# N32G003 register map
Vendor: Nationstech Ltd.; File version: 1.0
Registers are 32-bit, read-write, reset 0x0 unless marked. A register's access mark holds for its fields unless they carry their own. Offsets are from the block's base; [hi:lo] are bit positions; {n}, {i} and the like mark numbered series.

## SPI — Serial peripheral interface
Base 0x40005800
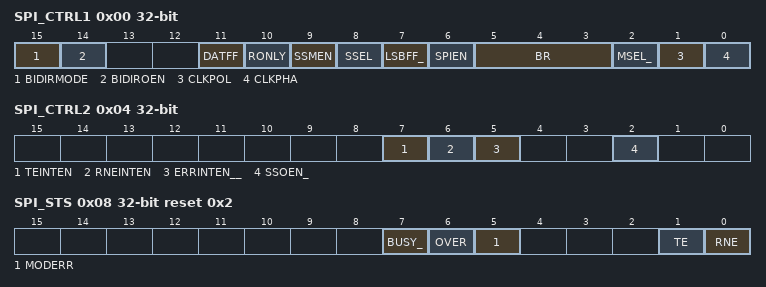
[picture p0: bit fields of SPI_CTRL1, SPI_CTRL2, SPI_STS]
0x00 SPI_CTRL1
  [15] BIDIRMODE, [14] BIDIROEN, [11] DATFF, [10] RONLY, [9] SSMEN, [8] SSEL, [7] LSBFF_, [6] SPIEN, [5:3] BR, [2] MSEL_, [1] CLKPOL, [0] CLKPHA
0x04 SPI_CTRL2
  [7] TEINTEN, [6] RNEINTEN, [5] ERRINTEN__, [2] SSOEN_
0x08 SPI_STS reset 0x2
  [7] BUSY_, [6] OVER, [5] MODERR, [1] TE, [0] RNE
0x0C SPI_DAT
  [15:0] DAT

## TIM1 — Advanced timer
Base 0x40000C00
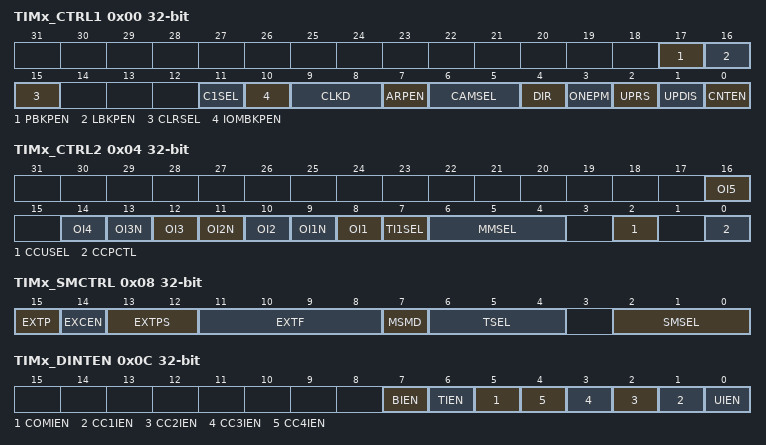
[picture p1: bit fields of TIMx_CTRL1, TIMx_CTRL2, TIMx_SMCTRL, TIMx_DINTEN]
0x00 TIMx_CTRL1
  [17] PBKPEN, [16] LBKPEN, [15] CLRSEL, [11] C1SEL, [10] IOMBKPEN, [9:8] CLKD, [7] ARPEN, [6:5] CAMSEL, [4] DIR, [3] ONEPM, [2] UPRS, [1] UPDIS, [0] CNTEN
0x04 TIMx_CTRL2
  [2n+6] OI{n} (n=1..5), [13] OI3N, [11] OI2N, [9] OI1N, [7] TI1SEL, [6:4] MMSEL, [2] CCUSEL, [0] CCPCTL
0x08 TIMx_SMCTRL
  [15] EXTP, [14] EXCEN, [13:12] EXTPS, [11:8] EXTF, [7] MSMD, [6:4] TSEL, [2:0] SMSEL
0x0C TIMx_DINTEN
  [7] BIEN, [6] TIEN, [5] COMIEN, [n] CC{n}IEN (n=1..4), [0] UIEN
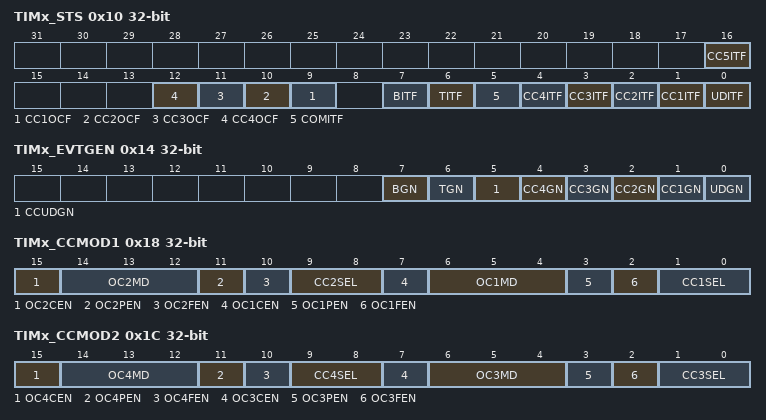
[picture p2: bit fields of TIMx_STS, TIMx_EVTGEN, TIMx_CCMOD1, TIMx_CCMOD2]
0x10 TIMx_STS
  [16] CC5ITF, [n+8] CC{n}OCF (n=1..4), [7] BITF, [6] TITF, [5] COMITF, [n] CC{n}ITF (n=1..4), [0] UDITF
0x14 TIMx_EVTGEN
  [7] BGN, [6] TGN, [5] CCUDGN, [n] CC{n}GN (n=1..4), [0] UDGN
0x18 TIMx_CCMOD1
  [15] OC2CEN, [14:12] OC2MD, [11] OC2PEN, [10] OC2FEN, [9:8] CC2SEL, [7] OC1CEN, [6:4] OC1MD, [3] OC1PEN, [2] OC1FEN, [1:0] CC1SEL
0x1C TIMx_CCMOD2
  [15] OC4CEN
  [14:12] OC4MD — OC4M
  [11] OC4PEN
  [10] OC4FEN
  [9:8] CC4SEL
  [7] OC3CEN
  [6:4] OC3MD — OC3M
  [3] OC3PEN
  [2] OC3FEN
  [1:0] CC3SEL
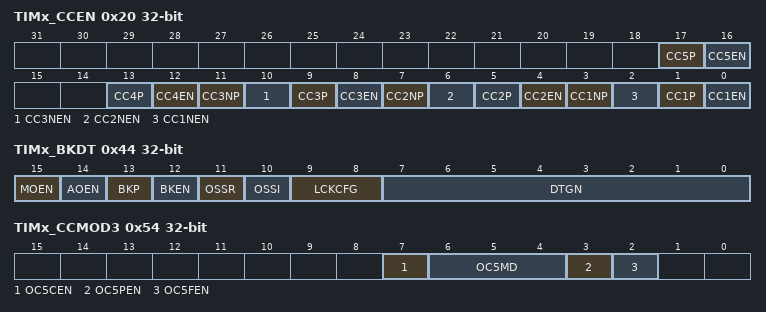
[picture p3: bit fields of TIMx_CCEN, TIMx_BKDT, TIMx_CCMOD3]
0x20 TIMx_CCEN
  [4n-3] CC{n}P (n=1..5), [4n-4] CC{n}EN (n=1..5), [11] CC3NP, [10] CC3NEN, [7] CC2NP, [6] CC2NEN, [3] CC1NP, [2] CC1NEN
0x24 TIMx_CNT
  [15:0] CNT
0x28 TIMx_PSC
  [15:0] PSC
0x2C TIMx_AR
  [15:0] AR
0x30 TIMx_REPCNT
  [7:0] REPCNT
{0x30+4i} TIMx_CCDAT{i} (i=1..4)
  [15:0] CCDAT{i}
0x44 TIMx_BKDT
  [15] MOEN, [14] AOEN, [13] BKP, [12] BKEN, [11] OSSR, [10] OSSI, [9:8] LCKCFG, [7:0] DTGN
0x54 TIMx_CCMOD3
  [7] OC5CEN, [6:4] OC5MD, [3] OC5PEN, [2] OC5FEN
0x58 TIMx_CCDAT5
  [15:0] CCDAT5

## TIM3 — General purpose timer
Base 0x40000400
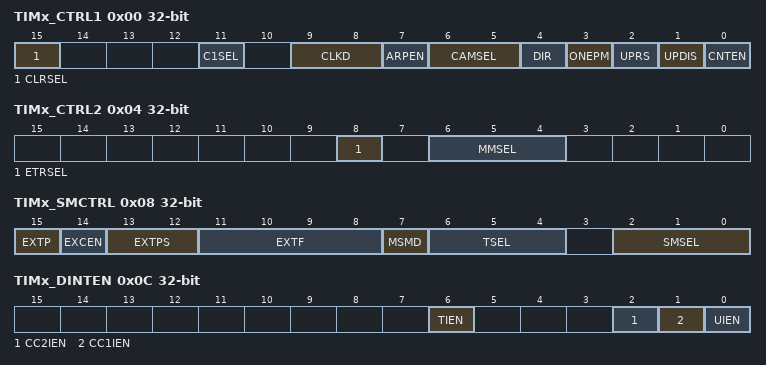
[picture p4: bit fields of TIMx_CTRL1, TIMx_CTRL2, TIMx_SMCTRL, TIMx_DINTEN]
0x00 TIMx_CTRL1
  [15] CLRSEL, [11] C1SEL, [9:8] CLKD, [7] ARPEN, [6:5] CAMSEL, [4] DIR, [3] ONEPM, [2] UPRS, [1] UPDIS, [0] CNTEN
0x04 TIMx_CTRL2
  [8] ETRSEL, [6:4] MMSEL
0x08 TIMx_SMCTRL
  [15] EXTP, [14] EXCEN, [13:12] EXTPS, [11:8] EXTF, [7] MSMD, [6:4] TSEL, [2:0] SMSEL
0x0C TIMx_DINTEN
  [6] TIEN, [2] CC2IEN, [1] CC1IEN, [0] UIEN
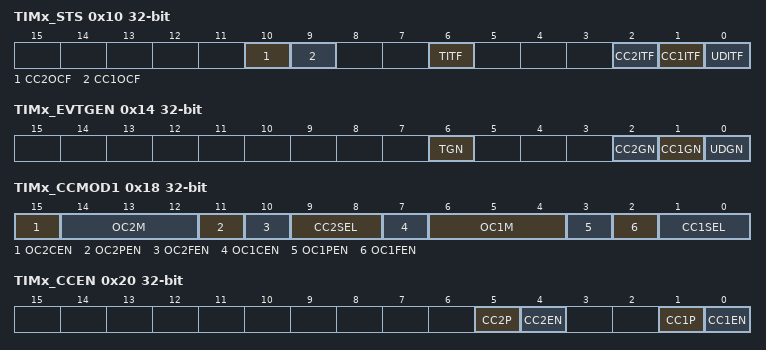
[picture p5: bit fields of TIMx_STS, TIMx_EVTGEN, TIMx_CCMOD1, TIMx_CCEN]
0x10 TIMx_STS
  [10] CC2OCF, [9] CC1OCF, [6] TITF, [2] CC2ITF, [1] CC1ITF, [0] UDITF
0x14 TIMx_EVTGEN
  [6] TGN, [2] CC2GN, [1] CC1GN, [0] UDGN
0x18 TIMx_CCMOD1
  [15] OC2CEN, [14:12] OC2M, [11] OC2PEN, [10] OC2FEN, [9:8] CC2SEL, [7] OC1CEN, [6:4] OC1M, [3] OC1PEN, [2] OC1FEN, [1:0] CC1SEL
0x20 TIMx_CCEN
  [5] CC2P, [4] CC2EN, [1] CC1P, [0] CC1EN
0x24 TIMx_CNT
  [15:0] CNT
0x28 TIMx_PSC
  [15:0] PSC
0x2C TIMx_AR
  [15:0] AR
0x34 TIMx_CCDAT1
  [15:0] CCDAT1
0x38 TIMx_CCDAT2
  [15:0] CCDAT2

## TIM6 — Basic timer
Base 0x40001000
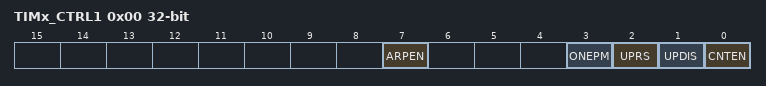
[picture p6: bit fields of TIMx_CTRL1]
0x00 TIMx_CTRL1
  [7] ARPEN, [3] ONEPM, [2] UPRS, [1] UPDIS, [0] CNTEN
0x0C TIMx_DINTEN
  [0] UIEN
0x10 TIMx_STS
  [0] UDITF
0x14 TIMx_EVTGEN
  [0] UDGN
0x24 TIMx_CNT
  [15:0] CNT
0x28 TIMx_PSC
  [15:0] PSC
0x2C TIMx_AR
  [15:0] AR

## UART1 — Universal asynchronous receiver transmitter
Base 0x40004400
Same registers: UART2 0x40004800
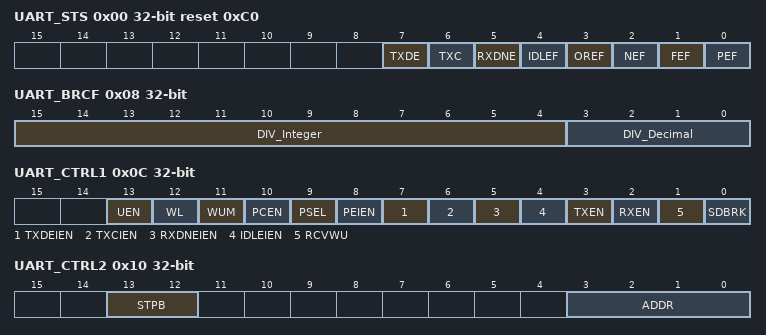
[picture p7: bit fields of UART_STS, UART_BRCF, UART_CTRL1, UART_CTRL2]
0x00 UART_STS reset 0xC0
  [7] TXDE, [6] TXC, [5] RXDNE, [4] IDLEF, [3] OREF, [2] NEF, [1] FEF, [0] PEF
0x04 UART_DAT
  [8:0] DATV
0x08 UART_BRCF
  [15:4] DIV_Integer, [3:0] DIV_Decimal
0x0C UART_CTRL1
  [13] UEN, [12] WL, [11] WUM, [10] PCEN, [9] PSEL, [8] PEIEN, [7] TXDEIEN, [6] TXCIEN, [5] RXDNEIEN, [4] IDLEIEN, [3] TXEN, [2] RXEN, [1] RCVWU, [0] SDBRK
0x10 UART_CTRL2
  [13:12] STPB, [3:0] ADDR
0x14 UART_CTRL3
  [3] HDMEN
